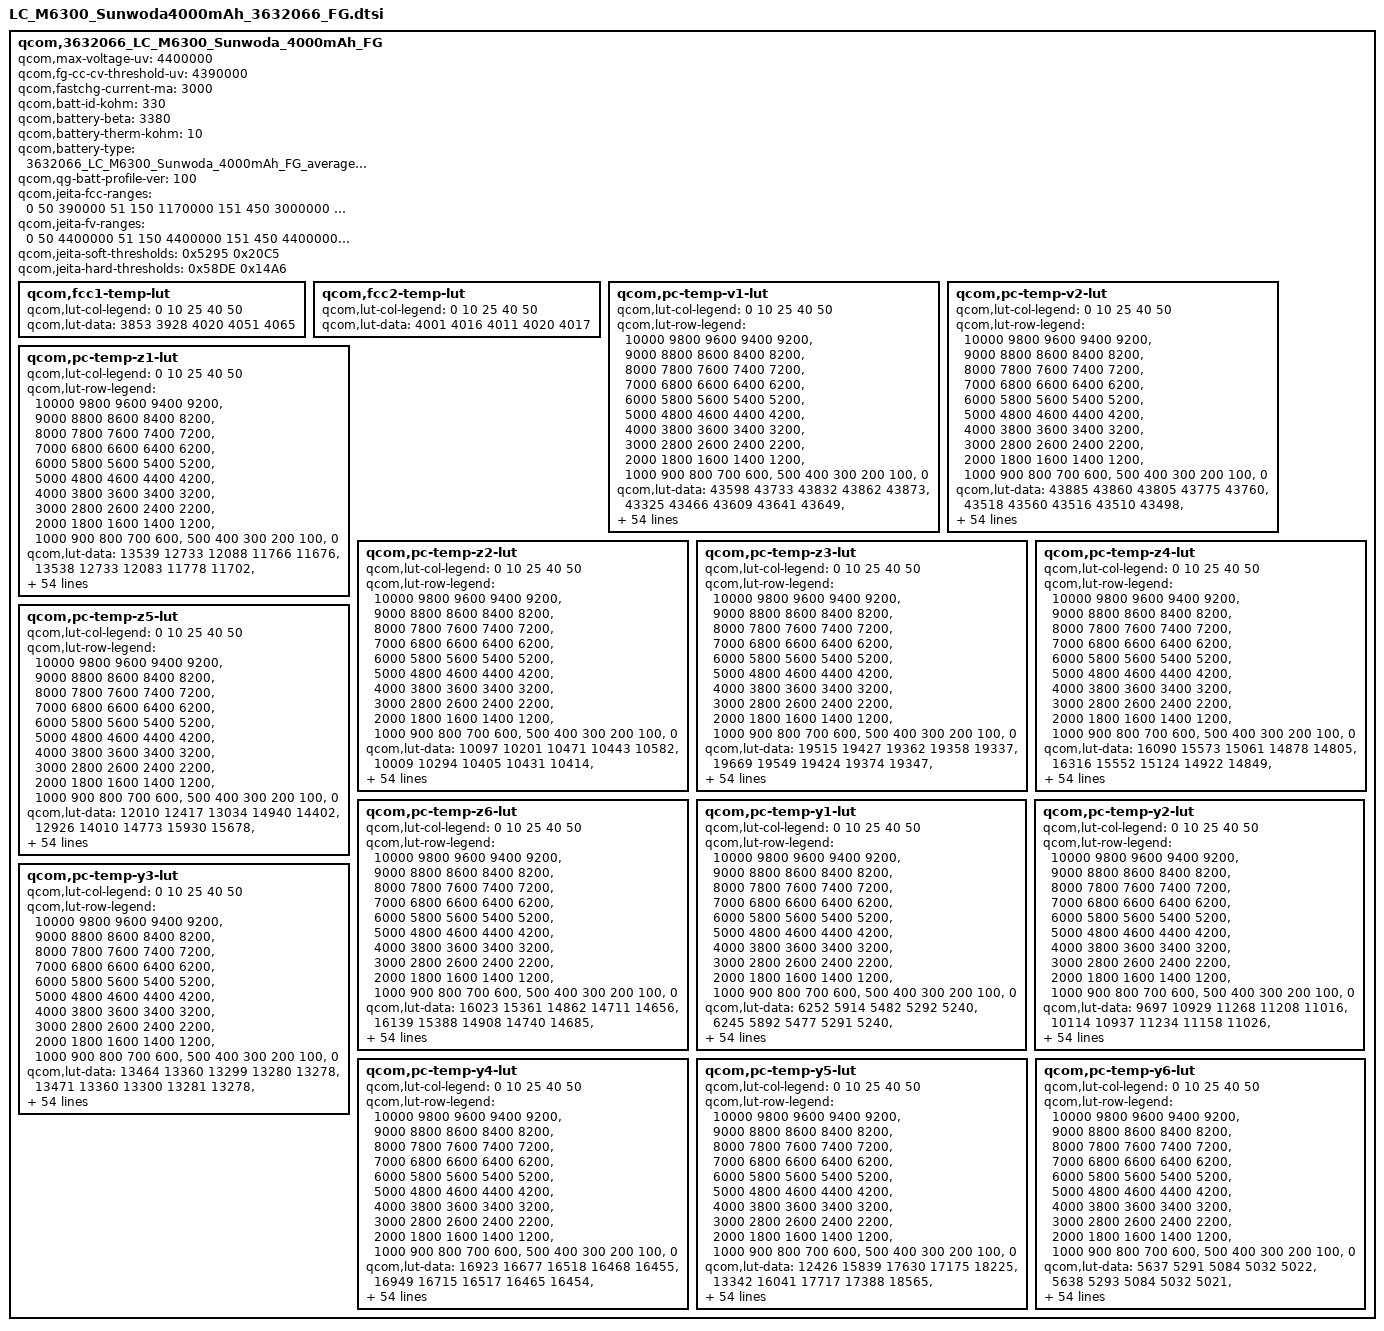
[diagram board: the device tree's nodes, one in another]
qcom,3632066_LC_M6300_Sunwoda_4000mAh_FG {
    /* 3632066_LC_M6300_Sunwoda_4000mAh_FG_averaged_MasterSlave_Oct17th2018 */
    qcom,max-voltage-uv = <4400000>;
    qcom,fg-cc-cv-threshold-uv = <4390000>;
    qcom,fastchg-current-ma = <3000>;
    qcom,batt-id-kohm = <330>;
    qcom,battery-beta = <3380>;
    qcom,battery-therm-kohm = <10>;
    qcom,battery-type = "3632066_LC_M6300_Sunwoda_4000mAh_FG_averaged_MasterSlave_Oct17th2018";
    qcom,qg-batt-profile-ver = <100>;

	qcom,jeita-fcc-ranges = <0   50  390000
				51  150   1170000
				151 450  3000000
				451 600  1950000>;
	qcom,jeita-fv-ranges = <0   50  4400000
				51  150  4400000
				151 450  4400000
				451 600  4100000>;


	/* COOL = 5 DegC, WARM = 45 DegC */
	qcom,jeita-soft-thresholds = <0x5295 0x20C5>;
	/* COLD = 0 DegC, HOT = 60 DegC */
	qcom,jeita-hard-thresholds = <0x58DE 0x14A6>;

	qcom,fcc1-temp-lut {
		qcom,lut-col-legend = <0 10 25 40 50>;
		qcom,lut-data = <3853 3928 4020 4051 4065>;
	};

	qcom,fcc2-temp-lut {
		qcom,lut-col-legend = <0 10 25 40 50>;
		qcom,lut-data = <4001 4016 4011 4020 4017>;
	};

	qcom,pc-temp-v1-lut {
		qcom,lut-col-legend = <0 10 25 40 50>;
		qcom,lut-row-legend = <10000 9800 9600 9400 9200>,
			<9000 8800 8600 8400 8200>,
			<8000 7800 7600 7400 7200>,
			<7000 6800 6600 6400 6200>,
			<6000 5800 5600 5400 5200>,
			<5000 4800 4600 4400 4200>,
			<4000 3800 3600 3400 3200>,
			<3000 2800 2600 2400 2200>,
			<2000 1800 1600 1400 1200>,
			<1000 900 800 700 600>,
			<500 400 300 200 100>,
			<0>;
		qcom,lut-data = <43598 43733 43832 43862 43873>,
			<43325 43466 43609 43641 43649>,
			<43072 43212 43364 43412 43422>,
			<42830 42969 43120 43178 43190>,
			<42594 42733 42876 42940 42956>,
			<42365 42498 42633 42698 42716>,
			<42145 42267 42394 42459 42479>,
			<41933 42043 42158 42222 42244>,
			<41729 41826 41929 41988 42012>,
			<41533 41617 41706 41757 41781>,
			<41349 41420 41489 41530 41551>,
			<41157 41234 41286 41308 41325>,
			<40941 41035 41091 41090 41103>,
			<40706 40807 40878 40876 40887>,
			<40458 40566 40627 40659 40679>,
			<40170 40318 40381 40447 40478>,
			<39918 40057 40174 40253 40284>,
			<39775 39862 39989 40076 40099>,
			<39676 39756 39830 39906 39921>,
			<39575 39667 39706 39752 39760>,
			<39460 39535 39571 39598 39601>,
			<39339 39350 39346 39399 39407>,
			<39201 39152 39062 39145 39164>,
			<39041 38933 38870 38933 38951>,
			<38884 38719 38750 38789 38797>,
			<38732 38601 38652 38670 38668>,
			<38590 38536 38559 38557 38552>,
			<38493 38482 38474 38452 38448>,
			<38426 38426 38395 38359 38355>,
			<38375 38376 38317 38275 38268>,
			<38335 38329 38249 38202 38190>,
			<38305 38284 38191 38137 38120>,
			<38277 38242 38141 38081 38058>,
			<38252 38207 38098 38030 38000>,
			<38230 38175 38064 37987 37950>,
			<38205 38143 38030 37944 37900>,
			<38182 38118 37995 37899 37845>,
			<38149 38086 37958 37851 37784>,
			<38093 38029 37904 37789 37713>,
			<38010 37934 37819 37705 37628>,
			<37911 37825 37716 37603 37529>,
			<37786 37703 37599 37489 37411>,
			<37643 37565 37463 37357 37274>,
			<37477 37403 37303 37199 37118>,
			<37343 37259 37162 37063 36988>,
			<37257 37176 37073 36979 36916>,
			<37237 37145 37050 36955 36893>,
			<37205 37130 37031 36940 36877>,
			<37175 37105 37018 36922 36858>,
			<37118 37051 36961 36859 36774>,
			<36875 36796 36693 36582 36464>,
			<36420 36348 36247 36141 36014>,
			<35836 35766 35662 35553 35426>,
			<35042 34969 34861 34741 34620>,
			<33781 33713 33604 33461 33357>,
			<30000 30000 30000 30000 30000>;
	};

	qcom,pc-temp-v2-lut {
		qcom,lut-col-legend = <0 10 25 40 50>;
		qcom,lut-row-legend = <10000 9800 9600 9400 9200>,
			<9000 8800 8600 8400 8200>,
			<8000 7800 7600 7400 7200>,
			<7000 6800 6600 6400 6200>,
			<6000 5800 5600 5400 5200>,
			<5000 4800 4600 4400 4200>,
			<4000 3800 3600 3400 3200>,
			<3000 2800 2600 2400 2200>,
			<2000 1800 1600 1400 1200>,
			<1000 900 800 700 600>,
			<500 400 300 200 100>,
			<0>;
		qcom,lut-data = <43885 43860 43805 43775 43760>,
			<43518 43560 43516 43510 43498>,
			<43187 43276 43241 43251 43242>,
			<42898 43008 42981 43000 42994>,
			<42646 42757 42736 42757 42753>,
			<42404 42513 42497 42517 42515>,
			<42166 42272 42259 42279 42278>,
			<41928 42035 42025 42043 42042>,
			<41654 41805 41795 41812 41811>,
			<41317 41579 41569 41583 41581>,
			<41115 41364 41348 41357 41355>,
			<41077 41168 41134 41134 41134>,
			<41052 40977 40923 40915 40917>,
			<40931 40769 40709 40708 40707>,
			<40506 40545 40490 40510 40502>,
			<40090 40309 40274 40314 40305>,
			<39834 40039 40050 40115 40117>,
			<39617 39774 39838 39921 39935>,
			<39427 39581 39680 39749 39763>,
			<39261 39434 39562 39596 39602>,
			<39095 39278 39422 39425 39425>,
			<38912 39085 39198 39199 39199>,
			<38725 38888 38947 38964 38965>,
			<38539 38722 38759 38781 38783>,
			<38343 38576 38605 38625 38629>,
			<38201 38446 38476 38493 38497>,
			<38125 38329 38367 38381 38384>,
			<38069 38222 38271 38282 38284>,
			<38021 38116 38181 38191 38191>,
			<37981 38010 38097 38109 38105>,
			<37944 37935 38021 38036 38029>,
			<37906 37887 37948 37969 37961>,
			<37868 37851 37883 37907 37899>,
			<37830 37817 37827 37842 37833>,
			<37791 37789 37779 37778 37769>,
			<37750 37758 37732 37707 37692>,
			<37704 37724 37686 37624 37587>,
			<37653 37685 37636 37537 37476>,
			<37593 37633 37573 37458 37389>,
			<37523 37564 37494 37384 37314>,
			<37442 37481 37405 37302 37233>,
			<37339 37370 37300 37204 37138>,
			<37218 37238 37180 37089 37027>,
			<37078 37079 37032 36948 36885>,
			<36963 36944 36911 36838 36785>,
			<36884 36871 36863 36803 36752>,
			<36851 36847 36847 36791 36739>,
			<36827 36819 36830 36775 36723>,
			<36784 36781 36798 36741 36688>,
			<36697 36684 36716 36629 36555>,
			<36477 36442 36456 36307 36200>,
			<36032 35986 35970 35800 35687>,
			<35407 35351 35349 35151 35026>,
			<34533 34480 34507 34271 34133>,
			<33128 33195 33087 32899 32682>,
			<27716 27763 27532 27535 27486>;
	};

	qcom,pc-temp-z1-lut {
		qcom,lut-col-legend = <0 10 25 40 50>;
		qcom,lut-row-legend = <10000 9800 9600 9400 9200>,
			<9000 8800 8600 8400 8200>,
			<8000 7800 7600 7400 7200>,
			<7000 6800 6600 6400 6200>,
			<6000 5800 5600 5400 5200>,
			<5000 4800 4600 4400 4200>,
			<4000 3800 3600 3400 3200>,
			<3000 2800 2600 2400 2200>,
			<2000 1800 1600 1400 1200>,
			<1000 900 800 700 600>,
			<500 400 300 200 100>,
			<0>;
		qcom,lut-data = <13539 12733 12088 11766 11676>,
			<13538 12733 12083 11778 11702>,
			<13521 12728 12078 11776 11705>,
			<13505 12722 12070 11774 11704>,
			<13495 12715 12058 11770 11702>,
			<13485 12704 12044 11766 11700>,
			<13476 12686 12034 11763 11699>,
			<13466 12672 12025 11759 11700>,
			<13454 12660 12022 11758 11701>,
			<13442 12648 12021 11758 11701>,
			<13427 12637 12022 11758 11700>,
			<13409 12628 12022 11759 11700>,
			<13382 12617 12022 11763 11700>,
			<13349 12603 12021 11766 11700>,
			<13320 12589 12006 11760 11700>,
			<13293 12582 11992 11750 11700>,
			<13273 12575 11992 11749 11701>,
			<13271 12572 11996 11753 11702>,
			<13280 12579 12002 11758 11704>,
			<13287 12592 12013 11761 11706>,
			<13303 12604 12022 11763 11708>,
			<13324 12620 12026 11765 11709>,
			<13327 12630 12029 11766 11710>,
			<13325 12632 12033 11768 11711>,
			<13324 12632 12039 11770 11713>,
			<13328 12633 12046 11774 11717>,
			<13332 12633 12051 11778 11720>,
			<13340 12634 12056 11783 11723>,
			<13363 12642 12063 11787 11726>,
			<13384 12657 12072 11790 11729>,
			<13378 12665 12079 11793 11733>,
			<13358 12667 12082 11797 11736>,
			<13349 12669 12085 11801 11738>,
			<13357 12674 12088 11805 11741>,
			<13371 12683 12092 11810 11744>,
			<13383 12690 12098 11814 11747>,
			<13399 12697 12104 11818 11750>,
			<13413 12702 12112 11821 11752>,
			<13422 12708 12118 11824 11755>,
			<13430 12716 12124 11828 11757>,
			<13447 12722 12131 11832 11760>,
			<13494 12736 12138 11835 11763>,
			<13507 12745 12147 11839 11766>,
			<13466 12743 12155 11842 11767>,
			<13460 12754 12170 11848 11769>,
			<13443 12771 12179 11852 11772>,
			<13441 12764 12179 11852 11771>,
			<13447 12760 12176 11854 11773>,
			<13460 12760 12172 11856 11775>,
			<13445 12775 12182 11861 11778>,
			<13459 12786 12195 11866 11783>,
			<13489 12791 12211 11874 11789>,
			<13483 12818 12229 11885 11797>,
			<13513 12845 12254 11900 11810>,
			<13513 12845 12254 11900 11810>,
			<13513 12845 12254 11900 11810>;
	};

	qcom,pc-temp-z2-lut {
		qcom,lut-col-legend = <0 10 25 40 50>;
		qcom,lut-row-legend = <10000 9800 9600 9400 9200>,
			<9000 8800 8600 8400 8200>,
			<8000 7800 7600 7400 7200>,
			<7000 6800 6600 6400 6200>,
			<6000 5800 5600 5400 5200>,
			<5000 4800 4600 4400 4200>,
			<4000 3800 3600 3400 3200>,
			<3000 2800 2600 2400 2200>,
			<2000 1800 1600 1400 1200>,
			<1000 900 800 700 600>,
			<500 400 300 200 100>,
			<0>;
		qcom,lut-data = <10097 10201 10471 10443 10582>,
			<10009 10294 10405 10431 10414>,
			<10070 10316 10449 10443 10399>,
			<10134 10293 10466 10452 10385>,
			<10138 10263 10451 10450 10389>,
			<10130 10237 10428 10437 10404>,
			<10122 10212 10398 10424 10403>,
			<10116 10194 10363 10408 10294>,
			<10110 10180 10352 10391 10187>,
			<10105 10172 10362 10378 10189>,
			<10100 10173 10377 10367 10213>,
			<10093 10180 10388 10366 10233>,
			<10072 10189 10399 10376 10250>,
			<10040 10203 10406 10387 10266>,
			<10030 10219 10414 10386 10281>,
			<10037 10226 10419 10377 10295>,
			<10049 10231 10409 10371 10309>,
			<10065 10237 10386 10351 10320>,
			<10086 10268 10381 10345 10335>,
			<10106 10314 10424 10374 10367>,
			<10120 10348 10483 10416 10410>,
			<10134 10378 10543 10454 10441>,
			<10151 10397 10605 10490 10463>,
			<10174 10405 10613 10517 10488>,
			<10195 10410 10527 10531 10591>,
			<10208 10409 10453 10544 10714>,
			<10218 10400 10491 10573 10698>,
			<10228 10393 10576 10620 10556>,
			<10236 10397 10599 10639 10436>,
			<10245 10407 10591 10570 10331>,
			<10255 10416 10581 10486 10246>,
			<10266 10427 10565 10466 10243>,
			<10277 10436 10542 10457 10267>,
			<10288 10445 10538 10456 10297>,
			<10299 10456 10546 10484 10343>,
			<10311 10464 10559 10531 10400>,
			<10326 10470 10581 10591 10457>,
			<10342 10477 10613 10669 10516>,
			<10363 10491 10640 10703 10552>,
			<10387 10515 10666 10712 10573>,
			<10408 10531 10682 10713 10586>,
			<10425 10538 10687 10704 10597>,
			<10449 10547 10688 10693 10604>,
			<10489 10565 10687 10698 10571>,
			<10768 10708 10728 10684 10551>,
			<10774 10784 10757 10625 10588>,
			<10665 10777 10738 10629 10585>,
			<10689 10821 10724 10640 10584>,
			<10605 10821 10723 10659 10650>,
			<10565 10857 10741 10752 10702>,
			<10590 10911 10843 10581 10423>,
			<10499 10912 10799 10476 10330>,
			<10306 10948 10764 10416 10257>,
			<10116 10888 10720 10337 10204>,
			<10116 10888 10720 10337 10204>,
			<10116 10888 10720 10337 10204>;
	};

	qcom,pc-temp-z3-lut {
		qcom,lut-col-legend = <0 10 25 40 50>;
		qcom,lut-row-legend = <10000 9800 9600 9400 9200>,
			<9000 8800 8600 8400 8200>,
			<8000 7800 7600 7400 7200>,
			<7000 6800 6600 6400 6200>,
			<6000 5800 5600 5400 5200>,
			<5000 4800 4600 4400 4200>,
			<4000 3800 3600 3400 3200>,
			<3000 2800 2600 2400 2200>,
			<2000 1800 1600 1400 1200>,
			<1000 900 800 700 600>,
			<500 400 300 200 100>,
			<0>;
		qcom,lut-data = <19515 19427 19362 19358 19337>,
			<19669 19549 19424 19374 19347>,
			<19744 19600 19458 19390 19363>,
			<19785 19618 19473 19401 19379>,
			<19794 19627 19479 19407 19387>,
			<19798 19629 19483 19412 19393>,
			<19799 19630 19482 19413 19394>,
			<19792 19630 19481 19413 19389>,
			<19780 19628 19478 19411 19383>,
			<19770 19625 19468 19405 19378>,
			<19762 19619 19458 19393 19372>,
			<19757 19609 19454 19389 19369>,
			<19760 19599 19452 19388 19368>,
			<19769 19588 19450 19388 19366>,
			<19771 19579 19448 19385 19362>,
			<19761 19576 19445 19381 19357>,
			<19744 19575 19440 19376 19353>,
			<19723 19573 19432 19368 19351>,
			<19696 19553 19424 19361 19349>,
			<19682 19527 19414 19356 19346>,
			<19682 19524 19408 19353 19343>,
			<19685 19536 19417 19354 19342>,
			<19690 19547 19438 19360 19343>,
			<19700 19553 19442 19363 19344>,
			<19707 19558 19421 19354 19353>,
			<19707 19557 19402 19341 19367>,
			<19706 19550 19405 19350 19374>,
			<19704 19543 19412 19389 19383>,
			<19700 19541 19423 19407 19387>,
			<19693 19540 19443 19405 19384>,
			<19687 19541 19457 19402 19377>,
			<19681 19543 19456 19397 19371>,
			<19674 19545 19452 19390 19366>,
			<19667 19544 19447 19382 19360>,
			<19660 19542 19440 19375 19353>,
			<19654 19539 19433 19370 19348>,
			<19646 19534 19429 19366 19347>,
			<19640 19528 19426 19364 19347>,
			<19633 19524 19422 19363 19347>,
			<19626 19519 19418 19363 19346>,
			<19619 19515 19415 19363 19345>,
			<19611 19512 19413 19361 19347>,
			<19600 19507 19410 19359 19351>,
			<19586 19498 19406 19359 19352>,
			<19513 19471 19395 19355 19349>,
			<19443 19446 19387 19343 19330>,
			<19322 19448 19382 19340 19327>,
			<19314 19431 19382 19336 19325>,
			<19304 19433 19369 19331 19318>,
			<19293 19429 19362 19328 19325>,
			<19310 19413 19350 19346 19344>,
			<19310 19406 19353 19351 19346>,
			<19315 19364 19350 19351 19348>,
			<19316 19324 19342 19354 19351>,
			<19316 19324 19342 19354 19351>,
			<19316 19324 19342 19354 19351>;
	};

	qcom,pc-temp-z4-lut {
		qcom,lut-col-legend = <0 10 25 40 50>;
		qcom,lut-row-legend = <10000 9800 9600 9400 9200>,
			<9000 8800 8600 8400 8200>,
			<8000 7800 7600 7400 7200>,
			<7000 6800 6600 6400 6200>,
			<6000 5800 5600 5400 5200>,
			<5000 4800 4600 4400 4200>,
			<4000 3800 3600 3400 3200>,
			<3000 2800 2600 2400 2200>,
			<2000 1800 1600 1400 1200>,
			<1000 900 800 700 600>,
			<500 400 300 200 100>,
			<0>;
		qcom,lut-data = <16090 15573 15061 14878 14805>,
			<16316 15552 15124 14922 14849>,
			<16121 15497 15064 14898 14839>,
			<15850 15348 15004 14864 14822>,
			<15667 15187 14945 14836 14803>,
			<15514 15092 14892 14808 14780>,
			<15389 15019 14854 14783 14761>,
			<15290 14960 14823 14761 14746>,
			<15208 14910 14799 14744 14734>,
			<15144 14871 14779 14735 14726>,
			<15093 14845 14764 14729 14720>,
			<15045 14825 14756 14725 14714>,
			<14982 14808 14750 14721 14707>,
			<14920 14789 14746 14718 14701>,
			<14904 14775 14744 14713 14696>,
			<14914 14774 14741 14708 14691>,
			<14924 14779 14733 14700 14686>,
			<14912 14781 14718 14689 14679>,
			<14867 14761 14709 14682 14673>,
			<14827 14734 14704 14680 14669>,
			<14795 14732 14701 14678 14667>,
			<14772 14749 14733 14693 14679>,
			<14770 14773 14808 14761 14748>,
			<14782 14828 14846 14808 14792>,
			<14800 14895 14863 14822 14783>,
			<14832 14909 14871 14829 14766>,
			<14872 14893 14862 14815 14750>,
			<14883 14874 14836 14760 14724>,
			<14879 14858 14810 14725 14707>,
			<14872 14841 14779 14714 14700>,
			<14863 14826 14757 14708 14695>,
			<14848 14811 14750 14704 14691>,
			<14834 14799 14746 14702 14686>,
			<14820 14791 14744 14701 14685>,
			<14807 14784 14743 14702 14685>,
			<14794 14778 14742 14703 14687>,
			<14781 14769 14742 14705 14690>,
			<14772 14764 14742 14708 14696>,
			<14765 14764 14743 14711 14700>,
			<14760 14765 14747 14715 14702>,
			<14755 14766 14750 14718 14704>,
			<14750 14755 14742 14713 14698>,
			<14744 14740 14728 14705 14689>,
			<14733 14728 14721 14702 14689>,
			<14708 14698 14699 14694 14683>,
			<14752 14681 14675 14675 14672>,
			<14876 14672 14668 14668 14663>,
			<14879 14673 14655 14654 14647>,
			<14880 14660 14651 14639 14634>,
			<14885 14657 14657 14643 14630>,
			<14876 14691 14691 14651 14642>,
			<14898 14704 14689 14650 14642>,
			<14906 14755 14693 14650 14641>,
			<14919 14808 14701 14646 14637>,
			<14919 14808 14701 14646 14637>,
			<14919 14808 14701 14646 14637>;
	};

	qcom,pc-temp-z5-lut {
		qcom,lut-col-legend = <0 10 25 40 50>;
		qcom,lut-row-legend = <10000 9800 9600 9400 9200>,
			<9000 8800 8600 8400 8200>,
			<8000 7800 7600 7400 7200>,
			<7000 6800 6600 6400 6200>,
			<6000 5800 5600 5400 5200>,
			<5000 4800 4600 4400 4200>,
			<4000 3800 3600 3400 3200>,
			<3000 2800 2600 2400 2200>,
			<2000 1800 1600 1400 1200>,
			<1000 900 800 700 600>,
			<500 400 300 200 100>,
			<0>;
		qcom,lut-data = <12010 12417 13034 14940 14402>,
			<12926 14010 14773 15930 15678>,
			<13617 15050 15892 16836 16958>,
			<14199 15676 16709 17570 18387>,
			<14705 16227 17323 18241 19399>,
			<15148 16866 17833 18829 20256>,
			<15563 17531 18345 19381 20551>,
			<15934 18315 18843 19994 20293>,
			<16304 19392 19207 20345 20018>,
			<16767 20482 19428 20110 19960>,
			<17333 21266 19648 19648 19874>,
			<17997 21934 19990 19575 20045>,
			<19081 22611 20447 19937 20711>,
			<20391 23864 21014 20440 21213>,
			<20764 25044 21941 21248 21169>,
			<20207 24973 22616 22157 21057>,
			<19628 24100 22479 22203 21135>,
			<19596 23545 22072 21489 22010>,
			<19687 23506 21993 21031 23047>,
			<19857 23617 22902 21401 23968>,
			<21755 25770 24605 22111 24763>,
			<25494 35339 29670 22796 24608>,
			<30719 41810 37993 23692 22885>,
			<39651 41608 39441 24068 21109>,
			<45608 40587 29403 20550 19528>,
			<46454 38792 20569 15996 18198>,
			<46615 33866 19909 16293 18429>,
			<46083 30026 19655 19743 20341>,
			<44027 29370 20011 22737 22014>,
			<41602 29000 23846 24606 22928>,
			<39946 29096 28271 26138 23773>,
			<38521 30935 31162 27457 24883>,
			<37642 33252 33528 28633 26196>,
			<37104 35149 34398 29180 26901>,
			<36726 37096 34740 29415 27187>,
			<36591 37794 34882 29551 27333>,
			<36673 37872 34701 29371 27361>,
			<36940 37909 34168 28708 27365>,
			<38163 37837 33144 27793 27031>,
			<39919 37586 30343 26063 24903>,
			<40113 37369 28207 24436 23046>,
			<37941 37101 27857 23710 23718>,
			<36951 36576 27580 23247 24904>,
			<36991 34678 26183 22893 24520>,
			<32415 36326 27073 22416 23621>,
			<23546 31745 28971 21826 19631>,
			<12626 34066 27649 21876 19777>,
			<12444 26557 30360 22432 21858>,
			<12250 28620 25618 24845 24286>,
			<12044 29360 22979 22369 26925>,
			<12437 20703 16880 21485 24685>,
			<12207 18166 16503 21589 23802>,
			<12110 14584 15752 20632 23082>,
			<11927 12550 14681 20740 23126>,
			<11927 12550 14681 20740 23126>,
			<11927 12550 14681 20740 23126>;
	};

	qcom,pc-temp-z6-lut {
		qcom,lut-col-legend = <0 10 25 40 50>;
		qcom,lut-row-legend = <10000 9800 9600 9400 9200>,
			<9000 8800 8600 8400 8200>,
			<8000 7800 7600 7400 7200>,
			<7000 6800 6600 6400 6200>,
			<6000 5800 5600 5400 5200>,
			<5000 4800 4600 4400 4200>,
			<4000 3800 3600 3400 3200>,
			<3000 2800 2600 2400 2200>,
			<2000 1800 1600 1400 1200>,
			<1000 900 800 700 600>,
			<500 400 300 200 100>,
			<0>;
		qcom,lut-data = <16023 15361 14862 14711 14656>,
			<16139 15388 14908 14740 14685>,
			<16056 15385 14900 14736 14689>,
			<15935 15315 14888 14731 14691>,
			<15842 15230 14864 14723 14688>,
			<15755 15179 14838 14713 14681>,
			<15680 15137 14819 14703 14673>,
			<15618 15103 14803 14694 14665>,
			<15564 15074 14789 14685 14657>,
			<15519 15049 14774 14676 14650>,
			<15482 15029 14763 14668 14645>,
			<15447 15012 14758 14664 14640>,
			<15407 14995 14754 14662 14636>,
			<15367 14974 14750 14661 14632>,
			<15344 14957 14745 14656 14628>,
			<15333 14954 14740 14650 14623>,
			<15322 14953 14733 14643 14618>,
			<15301 14952 14724 14635 14614>,
			<15271 14936 14717 14629 14610>,
			<15253 14915 14711 14625 14607>,
			<15247 14914 14708 14623 14604>,
			<15243 14929 14728 14630 14609>,
			<15245 14949 14774 14665 14639>,
			<15259 14979 14788 14684 14659>,
			<15276 15011 14786 14685 14661>,
			<15293 15016 14783 14684 14662>,
			<15310 15008 14779 14683 14661>,
			<15315 14999 14775 14680 14655>,
			<15312 14992 14772 14677 14650>,
			<15308 14986 14770 14673 14645>,
			<15303 14981 14768 14668 14640>,
			<15298 14977 14766 14664 14636>,
			<15291 14974 14763 14660 14631>,
			<15284 14972 14760 14656 14628>,
			<15277 14971 14757 14653 14624>,
			<15272 14969 14754 14650 14622>,
			<15267 14965 14753 14650 14623>,
			<15264 14962 14752 14650 14625>,
			<15263 14962 14752 14651 14626>,
			<15263 14964 14753 14653 14627>,
			<15262 14965 14754 14655 14628>,
			<15262 14963 14751 14652 14627>,
			<15261 14959 14746 14648 14625>,
			<15256 14955 14742 14648 14626>,
			<15223 14937 14731 14643 14623>,
			<15207 14921 14718 14629 14608>,
			<15199 14919 14713 14625 14603>,
			<15196 14912 14708 14617 14595>,
			<15194 14910 14700 14608 14585>,
			<15198 14910 14702 14609 14587>,
			<15210 14923 14713 14623 14605>,
			<15227 14932 14718 14627 14608>,
			<15245 14942 14723 14629 14610>,
			<15272 14958 14728 14633 14613>,
			<15272 14958 14728 14633 14613>,
			<15272 14958 14728 14633 14613>;
	};

	qcom,pc-temp-y1-lut {
		qcom,lut-col-legend = <0 10 25 40 50>;
		qcom,lut-row-legend = <10000 9800 9600 9400 9200>,
			<9000 8800 8600 8400 8200>,
			<8000 7800 7600 7400 7200>,
			<7000 6800 6600 6400 6200>,
			<6000 5800 5600 5400 5200>,
			<5000 4800 4600 4400 4200>,
			<4000 3800 3600 3400 3200>,
			<3000 2800 2600 2400 2200>,
			<2000 1800 1600 1400 1200>,
			<1000 900 800 700 600>,
			<500 400 300 200 100>,
			<0>;
		qcom,lut-data = <6252 5914 5482 5292 5240>,
			<6245 5892 5477 5291 5240>,
			<6234 5868 5472 5289 5239>,
			<6222 5846 5467 5287 5238>,
			<6212 5830 5463 5285 5237>,
			<6207 5823 5459 5283 5236>,
			<6205 5824 5456 5281 5235>,
			<6204 5828 5454 5279 5234>,
			<6205 5828 5451 5277 5233>,
			<6209 5822 5447 5275 5233>,
			<6215 5817 5445 5274 5232>,
			<6229 5814 5444 5273 5231>,
			<6247 5812 5444 5272 5231>,
			<6248 5811 5443 5270 5231>,
			<6237 5806 5440 5267 5230>,
			<6229 5805 5439 5266 5230>,
			<6227 5811 5444 5269 5230>,
			<6226 5820 5451 5273 5231>,
			<6231 5824 5452 5274 5231>,
			<6251 5827 5451 5273 5231>,
			<6264 5829 5450 5272 5232>,
			<6251 5828 5452 5273 5232>,
			<6231 5827 5455 5275 5233>,
			<6229 5829 5459 5276 5234>,
			<6239 5832 5463 5279 5236>,
			<6244 5836 5468 5281 5238>,
			<6241 5839 5473 5283 5239>,
			<6236 5842 5480 5286 5241>,
			<6235 5842 5484 5289 5243>,
			<6234 5843 5488 5292 5245>,
			<6233 5844 5493 5296 5248>,
			<6234 5846 5499 5299 5251>,
			<6238 5850 5505 5303 5254>,
			<6243 5855 5511 5307 5257>,
			<6247 5864 5517 5311 5260>,
			<6249 5872 5523 5314 5262>,
			<6245 5878 5529 5317 5264>,
			<6238 5883 5535 5319 5266>,
			<6229 5888 5540 5322 5267>,
			<6218 5892 5545 5323 5270>,
			<6212 5895 5551 5326 5271>,
			<6222 5897 5564 5329 5273>,
			<6233 5898 5578 5333 5275>,
			<6230 5902 5590 5338 5277>,
			<6223 5895 5600 5345 5280>,
			<6250 5900 5599 5347 5283>,
			<6248 5901 5603 5350 5284>,
			<6251 5910 5608 5350 5283>,
			<6260 5901 5610 5349 5282>,
			<6272 5912 5624 5348 5282>,
			<6261 5908 5621 5349 5285>,
			<6274 5914 5630 5358 5290>,
			<6284 5921 5651 5368 5296>,
			<6320 5921 5668 5380 5304>,
			<6320 5921 5668 5380 5304>,
			<6320 5921 5668 5380 5304>;
	};

	qcom,pc-temp-y2-lut {
		qcom,lut-col-legend = <0 10 25 40 50>;
		qcom,lut-row-legend = <10000 9800 9600 9400 9200>,
			<9000 8800 8600 8400 8200>,
			<8000 7800 7600 7400 7200>,
			<7000 6800 6600 6400 6200>,
			<6000 5800 5600 5400 5200>,
			<5000 4800 4600 4400 4200>,
			<4000 3800 3600 3400 3200>,
			<3000 2800 2600 2400 2200>,
			<2000 1800 1600 1400 1200>,
			<1000 900 800 700 600>,
			<500 400 300 200 100>,
			<0>;
		qcom,lut-data = <9697 10929 11268 11208 11016>,
			<10114 10937 11234 11158 11026>,
			<10378 10940 11202 11109 11027>,
			<10523 10940 11171 11063 11022>,
			<10585 10937 11142 11023 11012>,
			<10598 10932 11115 10991 10999>,
			<10487 10914 11088 10964 10961>,
			<10316 10883 11064 10944 10913>,
			<10364 10849 11045 10932 10893>,
			<10783 10803 11030 10922 10883>,
			<11053 10781 11015 10918 10878>,
			<10874 10801 10995 10918 10881>,
			<10598 10845 10977 10923 10886>,
			<10569 10925 10983 10938 10881>,
			<10701 11090 11029 10970 10867>,
			<10835 11177 11085 11008 10860>,
			<10916 11168 11149 11052 10923>,
			<10987 11154 11226 11105 11033>,
			<11057 11165 11309 11176 11118>,
			<11134 11217 11410 11272 11200>,
			<11170 11245 11457 11322 11236>,
			<11139 11242 11414 11328 11237>,
			<11065 11237 11354 11325 11237>,
			<10945 11238 11345 11306 11237>,
			<10685 11248 11348 11262 11237>,
			<10492 11251 11353 11242 11240>,
			<10280 11234 11374 11277 11254>,
			<9996 11212 11404 11334 11276>,
			<9867 11219 11428 11380 11310>,
			<9789 11255 11454 11423 11366>,
			<9742 11273 11469 11467 11408>,
			<9718 11254 11476 11533 11434>,
			<9702 11223 11479 11587 11453>,
			<9691 11194 11472 11579 11462>,
			<9681 11159 11452 11528 11465>,
			<9674 11128 11426 11478 11457>,
			<9670 11101 11394 11398 11421>,
			<9666 11071 11353 11328 11368>,
			<9664 11026 11308 11329 11323>,
			<9662 10960 11254 11350 11277>,
			<9661 10887 11199 11357 11241>,
			<9660 10814 11142 11322 11210>,
			<9659 10698 11086 11278 11201>,
			<9658 10291 11031 11237 11235>,
			<9658 9875 10961 11128 11143>,
			<9658 9919 10958 11056 10975>,
			<9658 9858 10938 11050 10971>,
			<9657 9755 10927 11073 10976>,
			<9657 9707 10902 11090 11015>,
			<9657 9691 10868 11086 10994>,
			<9656 9681 10834 11035 10912>,
			<9656 9673 10755 10983 10842>,
			<9655 9666 10707 10932 10769>,
			<9654 9660 10641 10861 10690>,
			<9654 9660 10641 10861 10690>,
			<9654 9660 10641 10861 10690>;
	};

	qcom,pc-temp-y3-lut {
		qcom,lut-col-legend = <0 10 25 40 50>;
		qcom,lut-row-legend = <10000 9800 9600 9400 9200>,
			<9000 8800 8600 8400 8200>,
			<8000 7800 7600 7400 7200>,
			<7000 6800 6600 6400 6200>,
			<6000 5800 5600 5400 5200>,
			<5000 4800 4600 4400 4200>,
			<4000 3800 3600 3400 3200>,
			<3000 2800 2600 2400 2200>,
			<2000 1800 1600 1400 1200>,
			<1000 900 800 700 600>,
			<500 400 300 200 100>,
			<0>;
		qcom,lut-data = <13464 13360 13299 13280 13278>,
			<13471 13360 13300 13281 13278>,
			<13477 13360 13301 13282 13279>,
			<13480 13361 13302 13283 13279>,
			<13483 13362 13303 13284 13280>,
			<13484 13364 13304 13285 13281>,
			<13484 13367 13305 13286 13281>,
			<13482 13369 13306 13287 13282>,
			<13477 13369 13307 13287 13283>,
			<13457 13366 13308 13288 13284>,
			<13434 13364 13308 13289 13285>,
			<13406 13371 13310 13290 13286>,
			<13380 13381 13312 13290 13287>,
			<13380 13378 13312 13291 13287>,
			<13405 13357 13313 13294 13288>,
			<13421 13346 13313 13296 13288>,
			<13413 13347 13311 13295 13290>,
			<13396 13349 13307 13293 13292>,
			<13386 13348 13307 13293 13292>,
			<13378 13344 13308 13293 13291>,
			<13371 13340 13309 13292 13290>,
			<13362 13335 13306 13290 13286>,
			<13352 13330 13300 13286 13281>,
			<13341 13327 13296 13283 13279>,
			<13318 13325 13294 13281 13278>,
			<13304 13323 13293 13280 13277>,
			<13288 13320 13294 13279 13278>,
			<13268 13318 13294 13279 13278>,
			<13266 13316 13294 13279 13278>,
			<13272 13313 13293 13280 13277>,
			<13281 13312 13293 13280 13276>,
			<13308 13314 13293 13280 13276>,
			<13345 13315 13293 13280 13276>,
			<13366 13317 13293 13280 13277>,
			<13380 13320 13293 13281 13277>,
			<13397 13323 13293 13281 13277>,
			<13427 13326 13294 13280 13277>,
			<13465 13328 13296 13279 13276>,
			<13506 13330 13297 13279 13276>,
			<13553 13332 13297 13280 13277>,
			<13599 13335 13298 13281 13278>,
			<13645 13337 13300 13281 13279>,
			<13690 13340 13301 13281 13280>,
			<13731 13346 13303 13281 13278>,
			<13778 13358 13305 13282 13280>,
			<13731 13351 13305 13285 13283>,
			<13776 13364 13308 13289 13285>,
			<13828 13379 13313 13293 13288>,
			<13880 13403 13318 13295 13289>,
			<13938 13422 13322 13295 13287>,
			<13993 13437 13322 13292 13284>,
			<14054 13456 13322 13293 13286>,
			<14177 13529 13330 13297 13289>,
			<14304 13651 13339 13303 13295>,
			<14304 13651 13339 13303 13295>,
			<14304 13651 13339 13303 13295>;
	};

	qcom,pc-temp-y4-lut {
		qcom,lut-col-legend = <0 10 25 40 50>;
		qcom,lut-row-legend = <10000 9800 9600 9400 9200>,
			<9000 8800 8600 8400 8200>,
			<8000 7800 7600 7400 7200>,
			<7000 6800 6600 6400 6200>,
			<6000 5800 5600 5400 5200>,
			<5000 4800 4600 4400 4200>,
			<4000 3800 3600 3400 3200>,
			<3000 2800 2600 2400 2200>,
			<2000 1800 1600 1400 1200>,
			<1000 900 800 700 600>,
			<500 400 300 200 100>,
			<0>;
		qcom,lut-data = <16923 16677 16518 16468 16455>,
			<16949 16715 16517 16465 16454>,
			<16982 16744 16516 16463 16452>,
			<17016 16765 16515 16461 16451>,
			<17044 16777 16514 16460 16450>,
			<17060 16781 16513 16460 16449>,
			<17067 16772 16513 16460 16450>,
			<17071 16757 16513 16461 16450>,
			<17073 16755 16514 16462 16450>,
			<17071 16758 16519 16464 16451>,
			<17077 16762 16523 16467 16453>,
			<17275 16771 16524 16471 16455>,
			<17569 16788 16526 16476 16459>,
			<17562 16819 16531 16481 16463>,
			<17231 16882 16549 16488 16469>,
			<16981 16914 16569 16496 16475>,
			<16922 16840 16585 16508 16479>,
			<16887 16739 16601 16522 16484>,
			<16870 16728 16622 16540 16496>,
			<16862 16743 16651 16563 16521>,
			<16850 16751 16664 16572 16534>,
			<16807 16710 16617 16545 16517>,
			<16743 16646 16545 16504 16489>,
			<16692 16614 16515 16483 16473>,
			<16633 16595 16498 16468 16460>,
			<16604 16579 16492 16463 16455>,
			<16633 16568 16493 16464 16456>,
			<16674 16558 16495 16468 16457>,
			<16681 16538 16498 16472 16460>,
			<16677 16506 16502 16479 16468>,
			<16672 16492 16505 16487 16477>,
			<16664 16495 16503 16498 16487>,
			<16656 16501 16501 16507 16496>,
			<16657 16510 16501 16507 16500>,
			<16674 16528 16501 16504 16503>,
			<16690 16548 16502 16499 16503>,
			<16701 16572 16503 16482 16482>,
			<16710 16595 16505 16465 16457>,
			<16717 16612 16506 16465 16455>,
			<16724 16627 16505 16467 16458>,
			<16727 16632 16505 16469 16461>,
			<16718 16630 16513 16474 16465>,
			<16701 16627 16523 16477 16466>,
			<16677 16626 16530 16471 16458>,
			<16669 16635 16531 16465 16449>,
			<16660 16623 16516 16466 16454>,
			<16677 16640 16529 16476 16469>,
			<16697 16669 16545 16493 16493>,
			<16728 16704 16568 16521 16520>,
			<16762 16738 16587 16519 16509>,
			<16767 16747 16578 16483 16466>,
			<16730 16738 16564 16477 16462>,
			<16725 16739 16591 16493 16473>,
			<16734 16768 16629 16535 16513>,
			<16734 16768 16629 16535 16513>,
			<16734 16768 16629 16535 16513>;
	};

	qcom,pc-temp-y5-lut {
		qcom,lut-col-legend = <0 10 25 40 50>;
		qcom,lut-row-legend = <10000 9800 9600 9400 9200>,
			<9000 8800 8600 8400 8200>,
			<8000 7800 7600 7400 7200>,
			<7000 6800 6600 6400 6200>,
			<6000 5800 5600 5400 5200>,
			<5000 4800 4600 4400 4200>,
			<4000 3800 3600 3400 3200>,
			<3000 2800 2600 2400 2200>,
			<2000 1800 1600 1400 1200>,
			<1000 900 800 700 600>,
			<500 400 300 200 100>,
			<0>;
		qcom,lut-data = <12426 15839 17630 17175 18225>,
			<13342 16041 17717 17388 18565>,
			<14536 16238 17754 17541 18901>,
			<15731 16421 17751 17641 19191>,
			<16651 16579 17720 17695 19394>,
			<17019 16704 17673 17710 19469>,
			<16936 16814 17572 17658 19416>,
			<16724 16895 17392 17539 19311>,
			<16024 16863 17106 17377 19205>,
			<13603 16600 16571 17107 19024>,
			<12097 16203 16115 16779 18776>,
			<12887 15171 15855 16267 18389>,
			<14684 14006 15628 15780 17868>,
			<17172 14020 15359 15734 17238>,
			<21400 15051 14953 15866 16403>,
			<23729 16313 14639 15930 16007>,
			<22227 17871 14446 15227 16247>,
			<19936 19411 14311 14291 16578>,
			<19756 20107 14687 14226 16448>,
			<21109 20490 16669 14599 15709>,
			<22335 20920 18657 15213 15318>,
			<22910 21632 20280 17448 16762>,
			<23346 22387 21519 19894 18741>,
			<23154 22880 21503 20048 19235>,
			<20512 23255 20739 19449 19413>,
			<18670 23530 20313 18816 19465>,
			<16089 23922 20808 18001 19196>,
			<12383 24287 21469 17310 18677>,
			<11789 24051 21529 17238 17882>,
			<12037 22894 21389 17249 16543>,
			<12384 22261 21323 17275 15949>,
			<12944 21646 22017 17512 16057>,
			<13567 20798 22922 17968 16301>,
			<13834 20357 22951 18872 17049>,
			<13971 20013 22530 20472 18812>,
			<14110 19786 22103 21102 19821>,
			<14339 19506 21826 20447 20102>,
			<14572 19230 21517 19554 20250>,
			<14679 19123 20880 19085 20088>,
			<14754 19009 19682 18722 19529>,
			<14798 18861 18526 18275 19188>,
			<14823 18591 17484 17334 19013>,
			<14835 18332 16768 16949 18963>,
			<14381 16855 16366 17407 19565>,
			<14245 15159 16439 17679 20062>,
			<14155 14881 17594 17658 18782>,
			<13900 14834 16841 17698 18110>,
			<14226 14266 16721 17919 17852>,
			<14160 14388 16408 17602 17029>,
			<14243 14550 16570 17718 16725>,
			<14499 14736 17310 19308 17956>,
			<14298 14475 18203 20618 19287>,
			<14200 14482 18556 22051 21327>,
			<14471 14675 18875 24264 25090>,
			<14471 14675 18875 24264 25090>,
			<14471 14675 18875 24264 25090>;
	};

	qcom,pc-temp-y6-lut {
		qcom,lut-col-legend = <0 10 25 40 50>;
		qcom,lut-row-legend = <10000 9800 9600 9400 9200>,
			<9000 8800 8600 8400 8200>,
			<8000 7800 7600 7400 7200>,
			<7000 6800 6600 6400 6200>,
			<6000 5800 5600 5400 5200>,
			<5000 4800 4600 4400 4200>,
			<4000 3800 3600 3400 3200>,
			<3000 2800 2600 2400 2200>,
			<2000 1800 1600 1400 1200>,
			<1000 900 800 700 600>,
			<500 400 300 200 100>,
			<0>;
		qcom,lut-data = <5637 5291 5084 5032 5022>,
			<5638 5293 5084 5032 5021>,
			<5638 5294 5084 5032 5021>,
			<5636 5294 5084 5032 5021>,
			<5635 5293 5083 5032 5022>,
			<5633 5292 5083 5032 5022>,
			<5628 5288 5083 5033 5022>,
			<5621 5283 5084 5033 5023>,
			<5609 5278 5084 5034 5024>,
			<5587 5274 5085 5036 5025>,
			<5575 5272 5086 5037 5026>,
			<5616 5277 5087 5038 5027>,
			<5678 5285 5089 5040 5029>,
			<5677 5290 5091 5042 5031>,
			<5610 5293 5097 5046 5032>,
			<5553 5294 5102 5049 5034>,
			<5530 5276 5105 5052 5037>,
			<5516 5250 5108 5055 5040>,
			<5511 5247 5113 5060 5044>,
			<5509 5248 5122 5066 5050>,
			<5506 5249 5127 5068 5052>,
			<5495 5234 5111 5058 5045>,
			<5477 5213 5086 5044 5033>,
			<5461 5204 5076 5036 5026>,
			<5444 5199 5070 5030 5022>,
			<5436 5195 5068 5028 5020>,
			<5444 5193 5069 5029 5020>,
			<5463 5192 5071 5029 5021>,
			<5484 5188 5073 5031 5022>,
			<5511 5182 5075 5033 5024>,
			<5542 5179 5076 5036 5026>,
			<5576 5185 5076 5040 5029>,
			<5615 5196 5077 5043 5032>,
			<5656 5208 5078 5043 5034>,
			<5701 5224 5079 5043 5035>,
			<5749 5244 5081 5042 5036>,
			<5798 5268 5084 5037 5029>,
			<5849 5295 5087 5032 5022>,
			<5900 5323 5090 5032 5022>,
			<5951 5353 5092 5034 5024>,
			<5998 5384 5096 5035 5025>,
			<6039 5415 5103 5038 5028>,
			<6076 5447 5111 5039 5028>,
			<6105 5481 5119 5038 5025>,
			<6144 5521 5128 5038 5025>,
			<6109 5498 5121 5041 5029>,
			<6148 5530 5129 5046 5035>,
			<6196 5567 5141 5054 5044>,
			<6245 5616 5153 5064 5052>,
			<6306 5656 5166 5063 5047>,
			<6352 5690 5166 5051 5034>,
			<6399 5735 5169 5050 5034>,
			<6503 5841 5201 5060 5041>,
			<6624 5990 5237 5078 5058>,
			<6624 5990 5237 5078 5058>,
			<6624 5990 5237 5078 5058>;
	};

};
